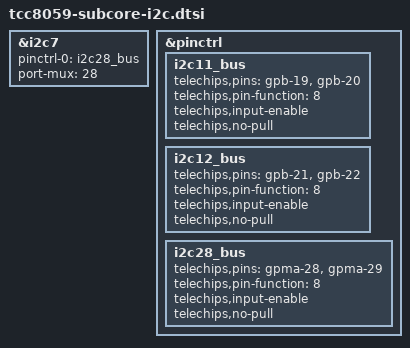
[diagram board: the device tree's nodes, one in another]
// SPDX-License-Identifier: (GPL-2.0-or-later OR MIT)
/*
 * Copyright (C) 2023 Telechips Inc.
 */

&i2c7 {
	pinctrl-names = "default";
	pinctrl-0 = <&i2c28_bus>;
	port-mux = <28>;
	status = "okay";
};

&pinctrl {
	/omit-if-no-ref/
	i2c11_bus: i2c11_bus {
		telechips,pins = "gpb-19", "gpb-20";
		telechips,pin-function = <8>;
		telechips,input-enable;
		telechips,no-pull;
	};

	/omit-if-no-ref/
	i2c12_bus: i2c12_bus {
		telechips,pins = "gpb-21", "gpb-22";
		telechips,pin-function = <8>;
		telechips,input-enable;
		telechips,no-pull;
	};

	/omit-if-no-ref/
	i2c28_bus: i2c28_bus {
		telechips,pins = "gpma-28", "gpma-29";
		telechips,pin-function = <8>;
		telechips,input-enable;
		telechips,no-pull;
	};
};
